# iostr736 register map
Registers are 16-bit, access not given, no defined reset value unless marked. A register's access mark holds for its fields unless they carry their own. Addresses are absolute; registers are grouped by the start of their names; [hi:lo] are bit positions; {n}, {i} and the like mark numbered series.

## TIM1
0xFFFFAC00 TIM1_ICAR
0xFFFFAC04 TIM1_ICBR
0xFFFFAC08 TIM1_OCAR
0xFFFFAC0C TIM1_OCBR
0xFFFFAC10 TIM1_CNTR
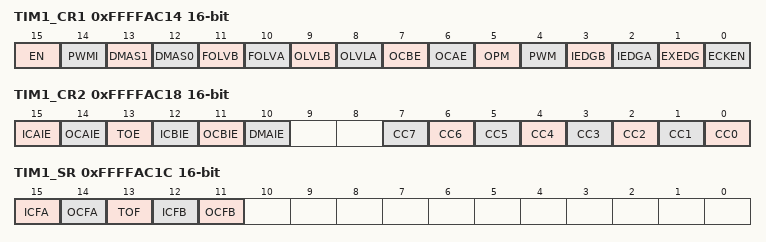
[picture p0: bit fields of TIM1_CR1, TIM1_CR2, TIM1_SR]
0xFFFFAC14 TIM1_CR1
  [15] EN, [14] PWMI, [13] DMAS1, [12] DMAS0, [11] FOLVB, [10] FOLVA, [9] OLVLB, [8] OLVLA, [7] OCBE, [6] OCAE, [5] OPM, [4] PWM, [3] IEDGB, [2] IEDGA, [1] EXEDG, [0] ECKEN
0xFFFFAC18 TIM1_CR2
  [15] ICAIE, [14] OCAIE, [13] TOE, [12] ICBIE, [11] OCBIE, [10] DMAIE, [n] CC{n} (n=0..7)
0xFFFFAC1C TIM1_SR
  [15] ICFA, [14] OCFA, [13] TOF, [12] ICFB, [11] OCFB

## TIM5
0xFFFFB000 TIM5_ICAR
0xFFFFB004 TIM5_ICBR
0xFFFFB008 TIM5_OCAR
0xFFFFB00C TIM5_OCBR
0xFFFFB010 TIM5_CNTR
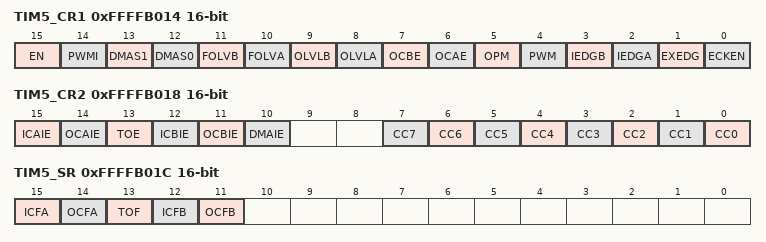
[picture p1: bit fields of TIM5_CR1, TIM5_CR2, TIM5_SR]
0xFFFFB014 TIM5_CR1
  [15] EN, [14] PWMI, [13] DMAS1, [12] DMAS0, [11] FOLVB, [10] FOLVA, [9] OLVLB, [8] OLVLA, [7] OCBE, [6] OCAE, [5] OPM, [4] PWM, [3] IEDGB, [2] IEDGA, [1] EXEDG, [0] ECKEN
0xFFFFB018 TIM5_CR2
  [15] ICAIE, [14] OCAIE, [13] TOE, [12] ICBIE, [11] OCBIE, [10] DMAIE, [n] CC{n} (n=0..7)
0xFFFFB01C TIM5_SR
  [15] ICFA, [14] OCFA, [13] TOF, [12] ICFB, [11] OCFB

## WIU
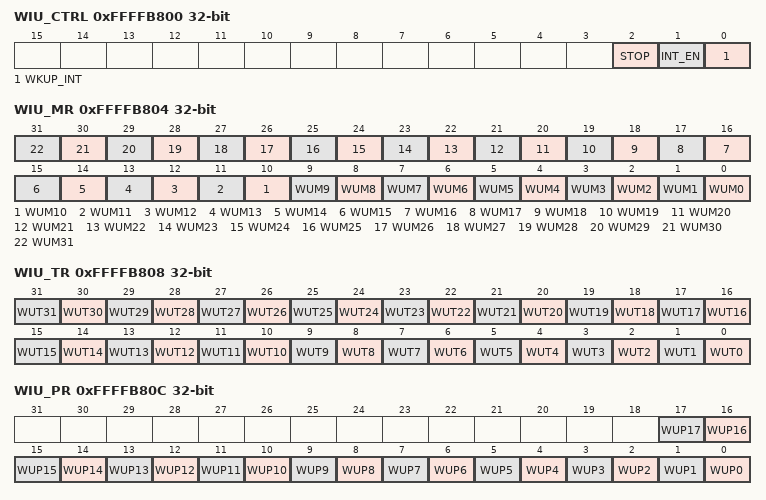
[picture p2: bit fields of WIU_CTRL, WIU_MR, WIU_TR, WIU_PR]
0xFFFFB800 WIU_CTRL 32-bit
  [2] STOP, [1] INT_EN, [0] WKUP_INT
0xFFFFB804 WIU_MR 32-bit
  [n] WUM{n} (n=0..31)
0xFFFFB808 WIU_TR 32-bit
  [n] WUT{n} (n=0..31)
0xFFFFB80C WIU_PR 32-bit
  [n] WUP{n} (n=0..17)
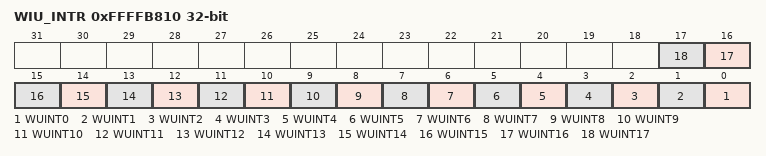
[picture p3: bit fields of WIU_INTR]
0xFFFFB810 WIU_INTR 32-bit
  [n] WUINT{n} (n=0..17)

## APB1
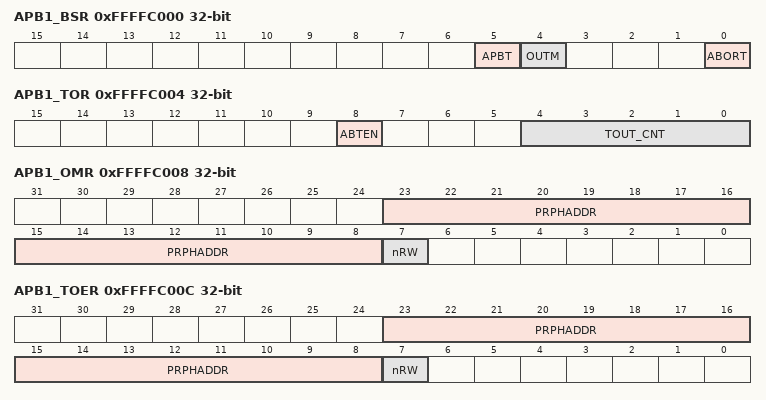
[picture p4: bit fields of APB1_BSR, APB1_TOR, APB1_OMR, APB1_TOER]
0xFFFFC000 APB1_BSR 32-bit
  [5] APBT, [4] OUTM, [0] ABORT
0xFFFFC004 APB1_TOR 32-bit
  [8] ABTEN, [4:0] TOUT_CNT
0xFFFFC008 APB1_OMR 32-bit
  [23:8] PRPHADDR, [7] nRW
0xFFFFC00C APB1_TOER 32-bit
  [23:8] PRPHADDR, [7] nRW

## PWM0
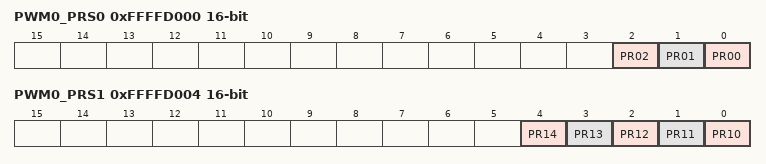
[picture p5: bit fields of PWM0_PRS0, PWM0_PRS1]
0xFFFFD000 PWM0_PRS0
  [2] PR02, [1] PR01, [0] PR00
0xFFFFD004 PWM0_PRS1
  [n-10] PR{n} (n=10..14)
0xFFFFD008 PWM0_PEN
  [0] PE
0xFFFFD00C PWM0_PLS
  [0] PL
0xFFFFD010 PWM0_CPI
  [0] CP
0xFFFFD014 PWM0_IM
  [0] IM
0xFFFFD01C PWM0_DUT
0xFFFFD020 PWM0_PER

## PWM1
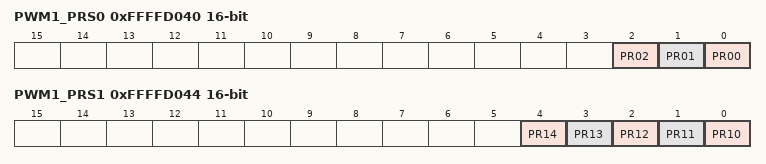
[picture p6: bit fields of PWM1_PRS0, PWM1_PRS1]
0xFFFFD040 PWM1_PRS0
  [2] PR02, [1] PR01, [0] PR00
0xFFFFD044 PWM1_PRS1
  [n-10] PR{n} (n=10..14)
0xFFFFD048 PWM1_PEN
  [0] PE
0xFFFFD04C PWM1_PLS
  [0] PL
0xFFFFD050 PWM1_CPI
  [0] CP
0xFFFFD054 PWM1_IM
  [0] IM
0xFFFFD05C PWM1_DUT
0xFFFFD060 PWM1_PER

## PWM2
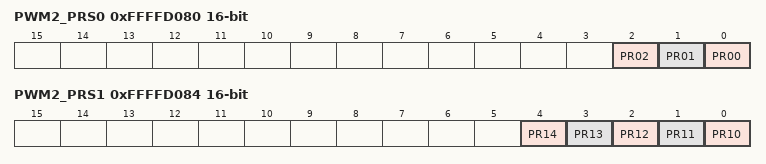
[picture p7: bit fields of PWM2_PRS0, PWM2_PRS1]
0xFFFFD080 PWM2_PRS0
  [2] PR02, [1] PR01, [0] PR00
0xFFFFD084 PWM2_PRS1
  [n-10] PR{n} (n=10..14)
0xFFFFD088 PWM2_PEN
  [0] PE
0xFFFFD08C PWM2_PLS
  [0] PL
0xFFFFD090 PWM2_CPI
  [0] CP
0xFFFFD094 PWM2_IM
  [0] IM
0xFFFFD09C PWM2_DUT
0xFFFFD0A0 PWM2_PER

## PWM3
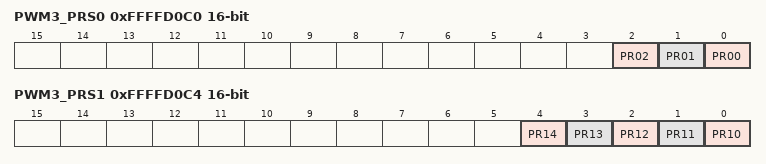
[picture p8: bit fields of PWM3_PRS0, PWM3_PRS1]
0xFFFFD0C0 PWM3_PRS0
  [2] PR02, [1] PR01, [0] PR00
0xFFFFD0C4 PWM3_PRS1
  [n-10] PR{n} (n=10..14)
0xFFFFD0C8 PWM3_PEN
  [0] PE
0xFFFFD0CC PWM3_PLS
  [0] PL
0xFFFFD0D0 PWM3_CPI
  [0] CP
0xFFFFD0D4 PWM3_IM
  [0] IM
0xFFFFD0DC PWM3_DUT
0xFFFFD0E0 PWM3_PER

## PWM4
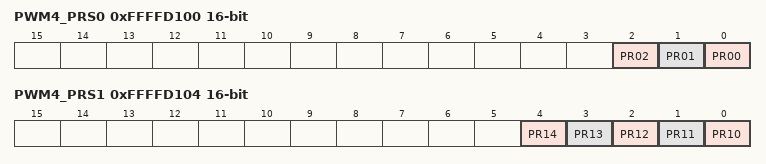
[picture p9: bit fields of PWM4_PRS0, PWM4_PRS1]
0xFFFFD100 PWM4_PRS0
  [2] PR02, [1] PR01, [0] PR00
0xFFFFD104 PWM4_PRS1
  [n-10] PR{n} (n=10..14)
0xFFFFD108 PWM4_PEN
  [0] PE
0xFFFFD10C PWM4_PLS
  [0] PL
0xFFFFD110 PWM4_CPI
  [0] CP
0xFFFFD114 PWM4_IM
  [0] IM
0xFFFFD11C PWM4_DUT
0xFFFFD120 PWM4_PER

## PWM5
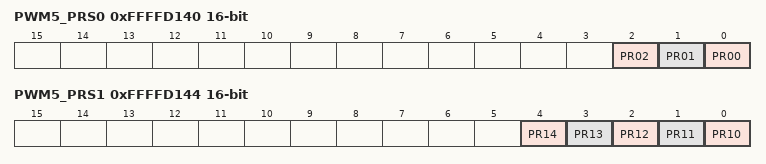
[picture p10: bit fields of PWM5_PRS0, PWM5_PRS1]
0xFFFFD140 PWM5_PRS0
  [2] PR02, [1] PR01, [0] PR00
0xFFFFD144 PWM5_PRS1
  [n-10] PR{n} (n=10..14)
0xFFFFD148 PWM5_PEN
  [0] PE
0xFFFFD14C PWM5_PLS
  [0] PL
0xFFFFD150 PWM5_CPI
  [0] CP
0xFFFFD154 PWM5_IM
  [0] IM
0xFFFFD15C PWM5_DUT
0xFFFFD160 PWM5_PER

## BSPI0
0xFFFFD800 BSPI0_RXR
0xFFFFD804 BSPI0_TXR
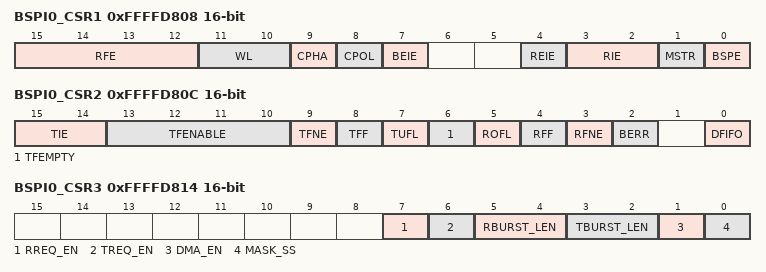
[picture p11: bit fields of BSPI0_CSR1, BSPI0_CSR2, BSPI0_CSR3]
0xFFFFD808 BSPI0_CSR1
  [15:12] RFE, [11:10] WL, [9] CPHA, [8] CPOL, [7] BEIE, [4] REIE, [3:2] RIE, [1] MSTR, [0] BSPE
0xFFFFD80C BSPI0_CSR2
  [15:14] TIE, [13:10] TFENABLE, [9] TFNE, [8] TFF, [7] TUFL, [6] TFEMPTY, [5] ROFL, [4] RFF, [3] RFNE, [2] BERR, [0] DFIFO
0xFFFFD810 BSPI0_CLK
  [7:0] DIV
0xFFFFD814 BSPI0_CSR3
  [7] RREQ_EN, [6] TREQ_EN, [5:4] RBURST_LEN, [3:2] TBURST_LEN, [1] DMA_EN, [0] MASK_SS
